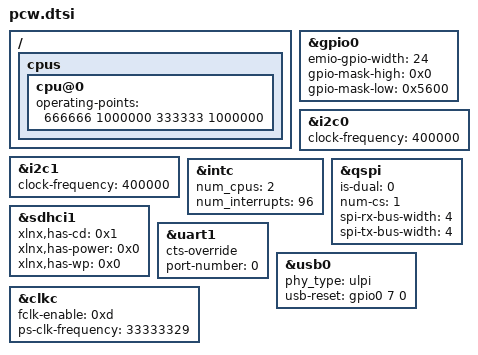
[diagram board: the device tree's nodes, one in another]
/*
 * CAUTION: This file is automatically generated by Xilinx.
 * Version: XSCT 2021.2
 * Today is: Sun Mar  6 03:19:21 2022
 */


/ {
	cpus {
		cpu@0 {
			operating-points = <666666 1000000 333333 1000000>;
		};
	};
};
&gpio0 {
	emio-gpio-width = <24>;
	gpio-mask-high = <0x0>;
	gpio-mask-low = <0x5600>;
};
&i2c0 {
	clock-frequency = <400000>;
	status = "okay";
};
&i2c1 {
	clock-frequency = <400000>;
	status = "okay";
};
&intc {
	num_cpus = <2>;
	num_interrupts = <96>;
};
&qspi {
	is-dual = <0>;
	num-cs = <1>;
	spi-rx-bus-width = <4>;
	spi-tx-bus-width = <4>;
	status = "okay";
};
&sdhci1 {
	status = "okay";
	xlnx,has-cd = <0x1>;
	xlnx,has-power = <0x0>;
	xlnx,has-wp = <0x0>;
};
&uart1 {
	cts-override ;
	device_type = "serial";
	port-number = <0>;
	status = "okay";
};
&usb0 {
	phy_type = "ulpi";
	status = "okay";
	usb-reset = <&gpio0 7 0>;
};
&clkc {
	fclk-enable = <0xd>;
	ps-clk-frequency = <33333329>;
};
